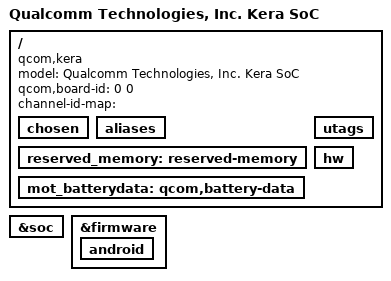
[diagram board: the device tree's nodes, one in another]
// SPDX-License-Identifier: BSD-3-Clause
/*
 * Copyright (c) 2023 Qualcomm Innovation Center, Inc. All rights reserved.
 */
/* This file is derivated from sun.dts */

/dts-v1/;

#include "kera.dtsi"

/ {
	model = "Qualcomm Technologies, Inc. Kera SoC";
    compatible = "qcom,kera";
    qcom,board-id = <0 0>;

/*
 * Moto common base dtb nodes definition
 */
	channel-id-map = "";
	chosen: chosen { };
	aliases: aliases { };
	reserved_memory: reserved-memory { };
	mot_batterydata: qcom,battery-data { };
	utags: utags { };
	hw: hw { };
};

&soc {
	/delete-node/ qcom_ramoops;
};

&reserved_memory {
	/delete-node/ ramoops-region;
};

&firmware {
	android {
		/delete-node/ fstab;
	};
};
